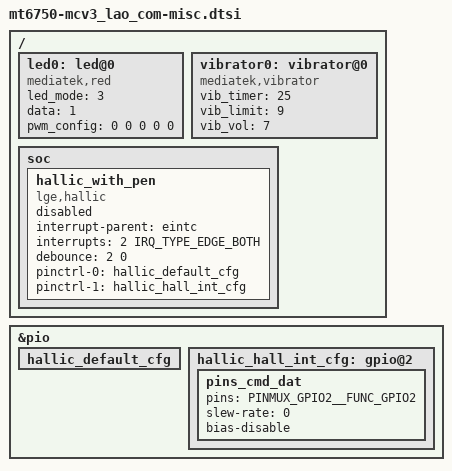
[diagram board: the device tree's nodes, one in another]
/*
 * LG Electronics CV3 misc device tree source
 *
 * Copyright (c) 2017 LG Electronics Co., Ltd.
 *              http://www.lge.com
 *
 */

/ {
	led0:led@0 {
        compatible = "mediatek,red";
        led_mode = <3>;
        data = <1>;
        pwm_config = <0 0 0 0 0>;
    };
};
/ {
	vibrator0:vibrator@0 {
		compatible = "mediatek,vibrator";
		vib_timer = <25>;
		vib_limit = <9>;
		vib_vol= <7>;
	};
};

&pio {
    hallic_default_cfg: hallic_default_cfg {
    };

    hallic_hall_int_cfg: gpio@2 {
        // HALL_INT
        pins_cmd_dat {
            pins = <PINMUX_GPIO2__FUNC_GPIO2>;
            slew-rate = <0>;        // input
            //bias-pull-down = <00>;
            bias-disable;
        };
    };
};

/ {
    soc {
        hallic_with_pen {
            compatible = "lge,hallic";

            interrupt-parent = <&eintc>;
            interrupts = <2 IRQ_TYPE_EDGE_BOTH>;
            debounce = <2 0>;    // gpio, debounce_time

            pinctrl-names = "default", "hall_int_cfg";
            pinctrl-0 = <&hallic_default_cfg>;
            pinctrl-1 = <&hallic_hall_int_cfg>;

            status = "disabled";
        };
    };
};
